# ADuCM350 register map
Vendor: Analog Devices; Series: ARMCM3; File version: 0.1
CPU: CM3 r2p1, little endian, no MPU, no FPU, 3 interrupt priority bits
Registers are 16-bit, access not given, no defined reset value unless marked. A register's access mark holds for its fields unless they carry their own. Offsets are from the block's base; [hi:lo] are bit positions.

## SPI0 — SPI0 Maste/Slave
Base 0x40004000
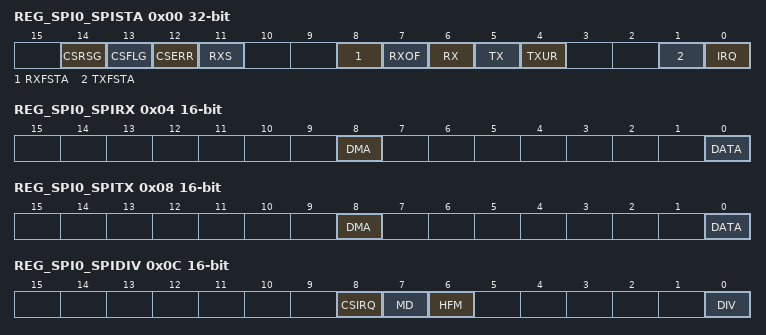
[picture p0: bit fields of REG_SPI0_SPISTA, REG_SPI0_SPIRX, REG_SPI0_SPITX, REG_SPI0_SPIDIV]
0x00 REG_SPI0_SPISTA 32-bit — SPI0 Status
  [14] CSRSG — Detected a rising edge on CS, in CONT mode
  [13] CSFLG — Detected a falling edge on CS, in CONT mode
  [12] CSERR — Detected a CS error condition
  [11] RXS — SPI Rx FIFO excess bytes present
  [8] RXFSTA — SPI Rx FIFO status
  [7] RXOF — SPI Rx FIFO overflow
  [6] RX — SPI Rx IRQ
  [5] TX — SPI Tx IRQ
  [4] TXUR — SPI Tx FIFO underflow
  [1] TXFSTA — SPI Tx FIFO status
  [0] IRQ — SPI Interrupt status
0x04 REG_SPI0_SPIRX — SPI0 Receive
  [8] DMA — 8-bit receive buffer
  [0] DATA — 8-bit receive buffer
0x08 REG_SPI0_SPITX — SPI0 Transmit
  [8] DMA — 8-bit transmit buffer
  [0] DATA — 8-bit transmit buffer
0x0C REG_SPI0_SPIDIV — SPI0 Baud rate selection
  [8] CSIRQ — Enable interrupt on every CS edge in CONT mode
  [7] MD — Reset Mode for CSERR
  [6] HFM — High Frequency Mode
  [0] DIV — SPI clock divider
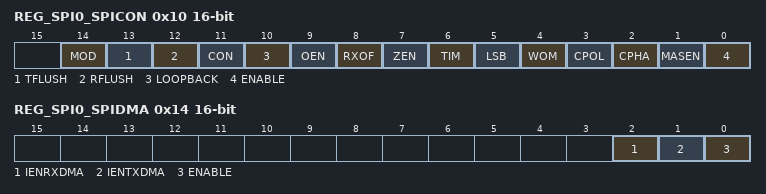
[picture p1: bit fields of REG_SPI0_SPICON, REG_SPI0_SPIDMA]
0x10 REG_SPI0_SPICON — SPI0 SPI configuration
  [14] MOD — SPI IRQ mode bits
  [13] TFLUSH — SPI Tx FIFO Flush enable
  [12] RFLUSH — SPI Rx FIFO Flush enable
  [11] CON — Continuous transfer enable
  [10] LOOPBACK — Loopback enable
  [9] OEN — Slave MISO output enable
  [8] RXOF — SPIRX overflow overwrite enable
  [7] ZEN — Transmit zeros enable
  [6] TIM — SPI transfer and interrupt mode
  [5] LSB — LSB first transfer enable
  [4] WOM — SPI Wired Or mode
  [3] CPOL — Serial Clock Polarity
  [2] CPHA — Serial clock phase mode
  [1] MASEN — Master mode enable
  [0] ENABLE — SPI enable
0x14 REG_SPI0_SPIDMA — SPI0 SPI DMA enable
  [2] IENRXDMA — Enable receive DMA request
  [1] IENTXDMA — Enable transmit DMA request
  [0] ENABLE — Enable DMA for data transfer
0x18 REG_SPI0_SPICNT — SPI0 Transfer byte count
  [0] COUNT — Transfer byte count

## SPI1 — SPI1 Master/Slave
Base 0x40004400
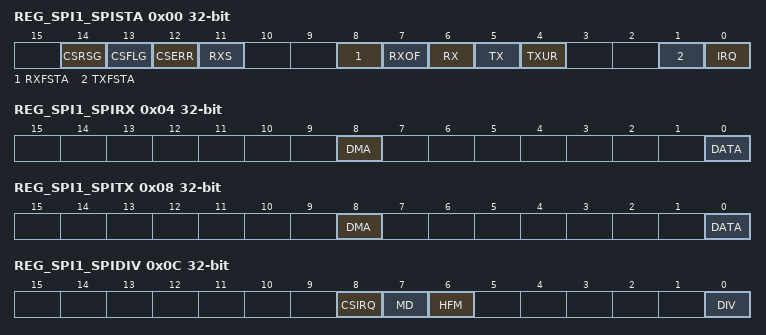
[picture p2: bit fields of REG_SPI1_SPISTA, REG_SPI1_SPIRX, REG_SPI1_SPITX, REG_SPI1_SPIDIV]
0x00 REG_SPI1_SPISTA 32-bit — SPI1 Status
  [14] CSRSG — Detected a rising edge on CS, in CONT mode
  [13] CSFLG — Detected a falling edge on CS, in CONT mode
  [12] CSERR — Detected a CS error condition
  [11] RXS — SPI Rx FIFO excess bytes present
  [8] RXFSTA — SPI Rx FIFO status
  [7] RXOF — SPI Rx FIFO overflow
  [6] RX — SPI Rx IRQ
  [5] TX — SPI Tx IRQ
  [4] TXUR — SPI Tx FIFO underflow
  [1] TXFSTA — SPI Tx FIFO status
  [0] IRQ — SPI Interrupt status
0x04 REG_SPI1_SPIRX 32-bit — SPI1 Receive
  [8] DMA — 8-bit receive buffer
  [0] DATA — 8-bit receive buffer
0x08 REG_SPI1_SPITX 32-bit — SPI1 Transmit
  [8] DMA — 8-bit transmit buffer
  [0] DATA — 8-bit transmit buffer
0x0C REG_SPI1_SPIDIV 32-bit — SPI1 Baud rate selection
  [8] CSIRQ — Enable interrupt on every CS edge in CONT mode
  [7] MD — Reset Mode for CSERR
  [6] HFM — High Frequency Mode
  [0] DIV — SPI clock divider
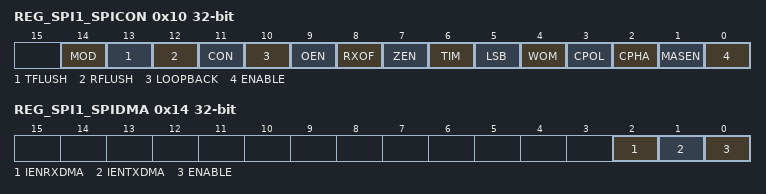
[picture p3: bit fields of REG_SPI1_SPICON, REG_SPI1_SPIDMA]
0x10 REG_SPI1_SPICON 32-bit — SPI1 SPI configuration
  [14] MOD — SPI IRQ mode bits
  [13] TFLUSH — SPI Tx FIFO Flush enable
  [12] RFLUSH — SPI Rx FIFO Flush enable
  [11] CON — Continuous transfer enable
  [10] LOOPBACK — Loopback enable
  [9] OEN — Slave MISO output enable
  [8] RXOF — SPIRX overflow overwrite enable
  [7] ZEN — Transmit zeros enable
  [6] TIM — SPI transfer and interrupt mode
  [5] LSB — LSB first transfer enable
  [4] WOM — SPI Wired Or mode
  [3] CPOL — Serial Clock Polarity
  [2] CPHA — Serial clock phase mode
  [1] MASEN — Master mode enable
  [0] ENABLE — SPI enable
0x14 REG_SPI1_SPIDMA 32-bit — SPI1 SPI DMA enable
  [2] IENRXDMA — Enable receive DMA request
  [1] IENTXDMA — Enable transmit DMA request
  [0] ENABLE — Enable DMA for data transfer
0x18 REG_SPI1_SPICNT 32-bit — SPI1 Transfer byte count
  [0] COUNT — Transfer byte count
